# PE register map
Registers from a debugger description file.
Registers are 32-bit, access not given, no defined reset value unless marked. A register's access mark holds for its fields unless they carry their own. Addresses are absolute; registers are grouped by the start of their names; lines under a group give offsets from that group; [hi:lo] are bit positions; {n}, {i} and the like mark numbered series; 'fields as' and 'values as' point back to an identical list; <NAME> marks a mode.

## PE
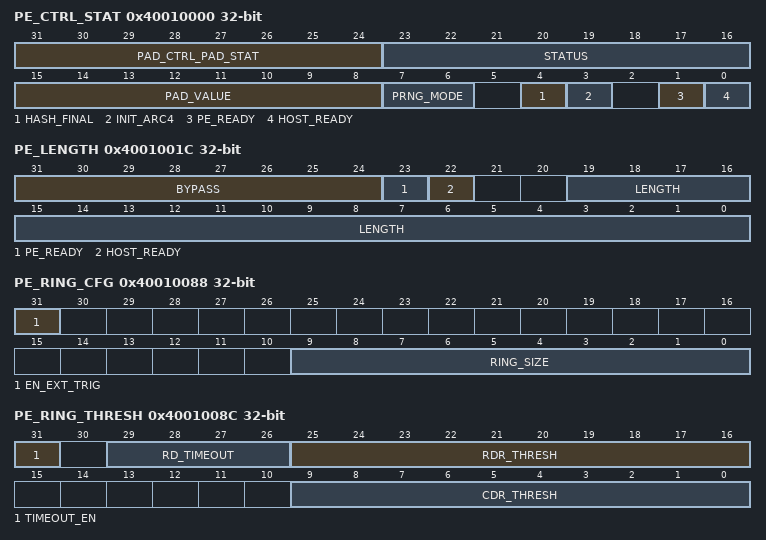
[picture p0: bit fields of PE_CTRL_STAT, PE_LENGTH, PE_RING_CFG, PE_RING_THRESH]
0x40010000 PE_CTRL_STAT
  [31:24] PAD_CTRL_PAD_STAT, [23:16] STATUS, [15:8] PAD_VALUE, [7:6] PRNG_MODE, [4] HASH_FINAL, [3] INIT_ARC4, [1] PE_READY, [0] HOST_READY
0x40010004 PE_SOURCE_ADDR
  [31:0] PACKET_SRC_ADDR
0x40010008 PE_DEST_ADDR
  [31:0] PACKET_DEST_ADDR
0x4001000C PE_SA_ADDR
  [31:0] SA_ADDR
0x40010010 PE_STATE_ADDR
  [31:0] STATE_ADDR
0x40010014 PE_ARC4_STATE_ADDR
  [31:0] ARC4_STATE_ADDR
0x40010018 PE_USER_ID
0x4001001C PE_LENGTH
  [31:24] BYPASS, [23] PE_READY, [22] HOST_READY, [19:0] LENGTH
0x40010080 PE_CDR_BASE
  [31:0] CDR_BASE_ADDR
0x40010084 PE_RDR_BASE
  [31:0] RDR_BASE_ADDR
0x40010088 PE_RING_CFG
  [31] EN_EXT_TRIG, [9:0] RING_SIZE
0x4001008C PE_RING_THRESH
  [31] TIMEOUT_EN, [29:26] RD_TIMEOUT, [25:16] RDR_THRESH, [9:0] CDR_THRESH
0x40010090 PE_CD_COUNT
  [10:0] CD_COUNT
0x40010094 PE_RD_COUNT
  [10:0] RD_COUNT
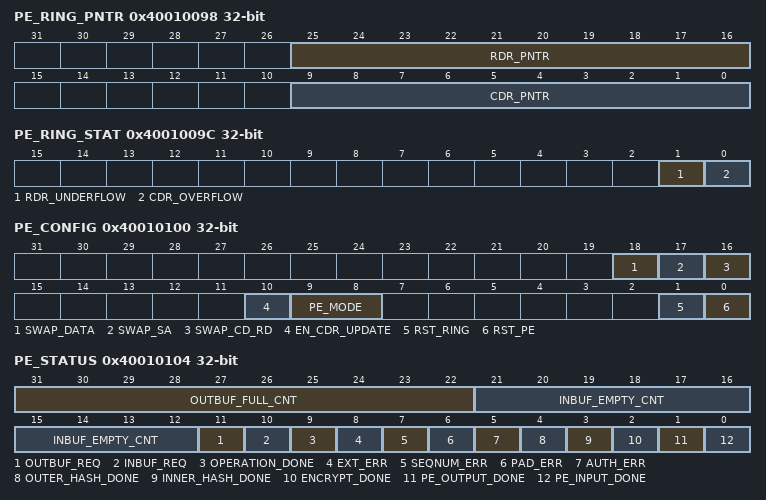
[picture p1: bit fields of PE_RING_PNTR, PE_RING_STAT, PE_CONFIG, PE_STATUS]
0x40010098 PE_RING_PNTR ro
  [25:16] RDR_PNTR, [9:0] CDR_PNTR
0x4001009C PE_RING_STAT
  [1] RDR_UNDERFLOW, [0] CDR_OVERFLOW
0x40010100 PE_CONFIG
  [18] SWAP_DATA, [17] SWAP_SA, [16] SWAP_CD_RD, [10] EN_CDR_UPDATE, [9:8] PE_MODE, [1] RST_RING, [0] RST_PE
0x40010104 PE_STATUS ro
  [31:22] OUTBUF_FULL_CNT, [21:12] INBUF_EMPTY_CNT, [11] OUTBUF_REQ, [10] INBUF_REQ, [9] OPERATION_DONE, [8] EXT_ERR, [7] SEQNUM_ERR, [6] PAD_ERR, [5] AUTH_ERR, [4] OUTER_HASH_DONE, [3] INNER_HASH_DONE, [2] ENCRYPT_DONE, [1] PE_OUTPUT_DONE, [0] PE_INPUT_DONE
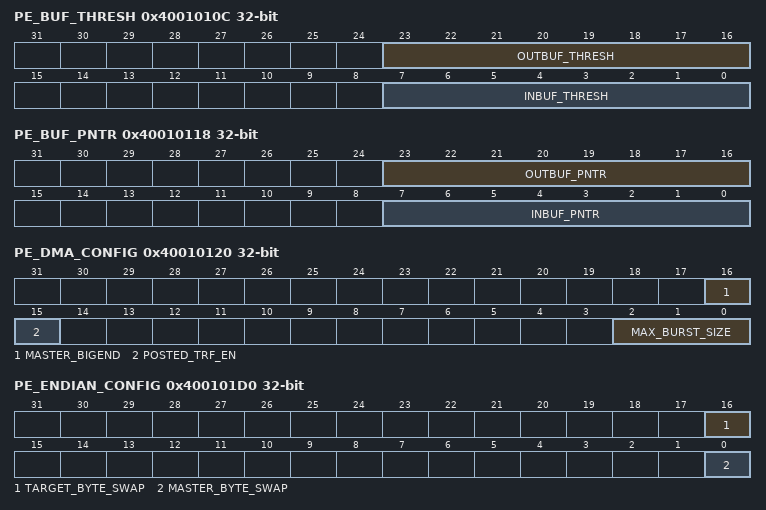
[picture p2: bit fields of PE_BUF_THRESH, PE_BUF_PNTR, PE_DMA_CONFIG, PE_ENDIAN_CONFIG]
0x4001010C PE_BUF_THRESH
  [23:16] OUTBUF_THRESH, [7:0] INBUF_THRESH
0x40010110 PE_INBUF_COUNT
  [8:0] INBUF_COUNT
0x40010114 PE_OUTBUF_COUNT
  [8:0] OUTBUF_COUNT
0x40010118 PE_BUF_PNTR ro
  [23:16] OUTBUF_PNTR, [7:0] INBUF_PNTR
0x40010120 PE_DMA_CONFIG
  [16] MASTER_BIGEND, [15] POSTED_TRF_EN, [2:0] MAX_BURST_SIZE
0x400101D0 PE_ENDIAN_CONFIG
  [16] TARGET_BYTE_SWAP, [0] MASTER_BYTE_SWAP
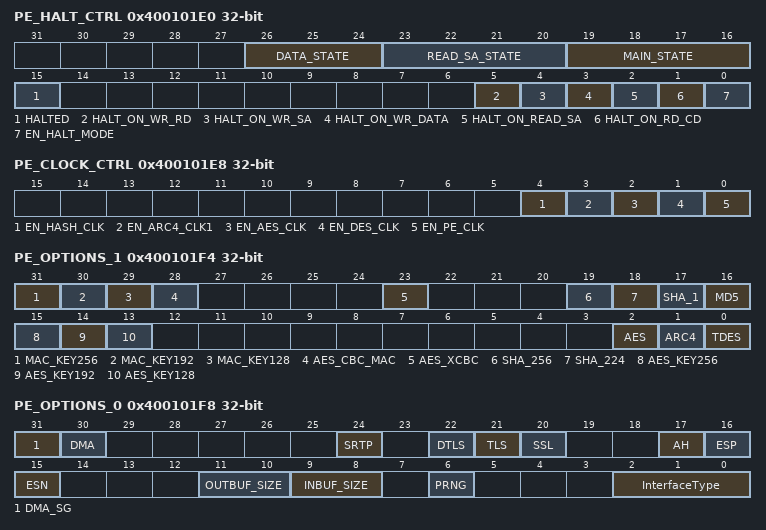
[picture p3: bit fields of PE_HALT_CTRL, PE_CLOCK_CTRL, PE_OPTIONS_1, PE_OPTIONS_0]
0x400101E0 PE_HALT_CTRL
  [26:24] DATA_STATE, [23:20] READ_SA_STATE, [19:16] MAIN_STATE, [15] HALTED, [5] HALT_ON_WR_RD, [4] HALT_ON_WR_SA, [3] HALT_ON_WR_DATA, [2] HALT_ON_READ_SA, [1] HALT_ON_RD_CD, [0] EN_HALT_MODE
0x400101E4 PE_CONTINUE wo
0x400101E8 PE_CLOCK_CTRL
  [4] EN_HASH_CLK, [3] EN_ARC4_CLK1, [2] EN_AES_CLK, [1] EN_DES_CLK, [0] EN_PE_CLK
0x400101F4 PE_OPTIONS_1 ro
  [31] MAC_KEY256, [30] MAC_KEY192, [29] MAC_KEY128, [28] AES_CBC_MAC, [23] AES_XCBC, [19] SHA_256, [18] SHA_224, [17] SHA_1, [16] MD5, [15] AES_KEY256, [14] AES_KEY192, [13] AES_KEY128, [2] AES, [1] ARC4, [0] TDES
0x400101F8 PE_OPTIONS_0 ro
  [31] DMA_SG, [30] DMA, [24] SRTP, [22] DTLS, [21] TLS, [20] SSL, [17] AH, [16] ESP, [15] ESN, [11:10] OUTBUF_SIZE, [9:8] INBUF_SIZE, [6] PRNG, [2:0] InterfaceType
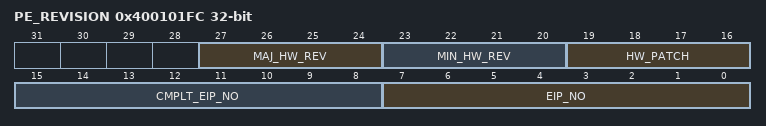
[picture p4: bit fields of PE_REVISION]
0x400101FC PE_REVISION ro
  [27:24] MAJ_HW_REV, [23:20] MIN_HW_REV, [19:16] HW_PATCH, [15:8] CMPLT_EIP_NO, [7:0] EIP_NO

## INT
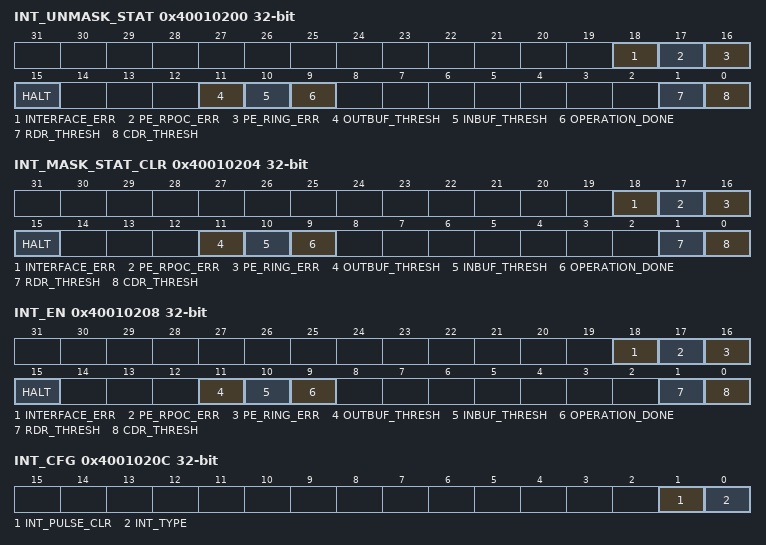
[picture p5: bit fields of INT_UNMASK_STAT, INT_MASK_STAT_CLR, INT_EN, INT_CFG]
0x40010200 INT_UNMASK_STAT ro
  [18] INTERFACE_ERR, [17] PE_RPOC_ERR, [16] PE_RING_ERR, [15] HALT, [11] OUTBUF_THRESH, [10] INBUF_THRESH, [9] OPERATION_DONE, [1] RDR_THRESH, [0] CDR_THRESH
0x40010204 INT_MASK_STAT_CLR
  fields as INT_UNMASK_STAT
0x40010208 INT_EN
  fields as INT_UNMASK_STAT
0x4001020C INT_CFG
  [1] INT_PULSE_CLR, [0] INT_TYPE
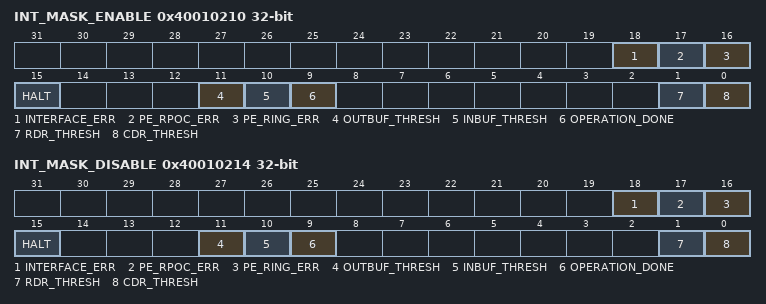
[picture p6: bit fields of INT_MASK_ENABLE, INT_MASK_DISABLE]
0x40010210 INT_MASK_ENABLE
  fields as INT_UNMASK_STAT
0x40010214 INT_MASK_DISABLE
  fields as INT_UNMASK_STAT

## SA
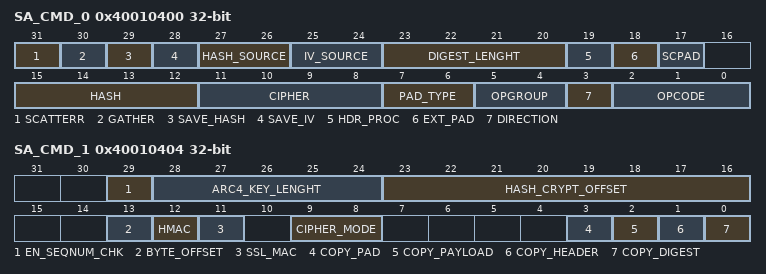
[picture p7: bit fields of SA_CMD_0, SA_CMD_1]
0x40010400 SA_CMD_0
  [31] SCATTERR, [30] GATHER, [29] SAVE_HASH, [28] SAVE_IV, [27:26] HASH_SOURCE, [25:24] IV_SOURCE, [23:20] DIGEST_LENGHT, [19] HDR_PROC, [18] EXT_PAD, [17] SCPAD, [15:12] HASH, [11:8] CIPHER, [7:6] PAD_TYPE, [5:4] OPGROUP, [3] DIRECTION, [2:0] OPCODE
0x40010404 SA_CMD_1
  [29] EN_SEQNUM_CHK, [28:24] ARC4_KEY_LENGHT, [23:16] HASH_CRYPT_OFFSET, [13] BYTE_OFFSET, [12] HMAC, [11] SSL_MAC, [9:8] CIPHER_MODE, [3] COPY_PAD, [2] COPY_PAYLOAD, [1] COPY_HEADER, [0] COPY_DIGEST
{0x40010408+4i} SA_KEY_{i} wo (i=0..7)
{0x40010428+4i} SA_IDIGEST_{i} (i=0..7)
{0x40010448+4i} SA_ODIGEST_{i} wo (i=0..7)
0x40010468 SA_SPI
0x4001046C SA_SEQNUM_0
0x40010470 SA_SEQNUM_1
0x40010474 SA_SEQNUMMASK_0
0x40010478 SA_SEQNUMMASK_1
0x4001047C SA_NONCE_READY_ARC4_IJ_PNTR

## STATE
{0x40010500+4i} STATE_IV_{i} (i=0..3)
0x40010510 STATE_BYTE_CNT_0
0x40010514 STATE_BYTE_CNT_1
{0x40010518+4i} STATE_IDIGEST_{i} (i=0..7)
